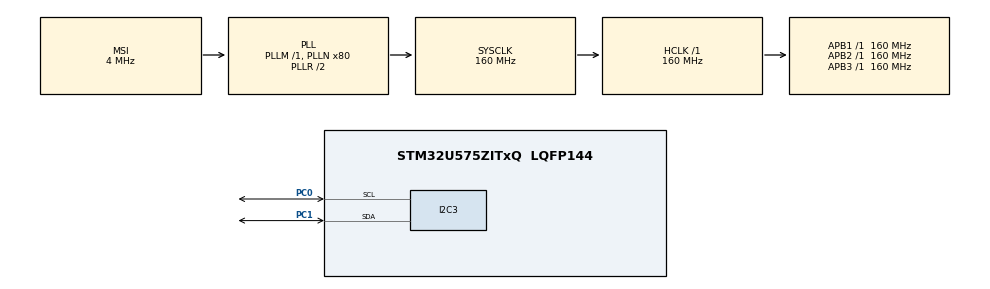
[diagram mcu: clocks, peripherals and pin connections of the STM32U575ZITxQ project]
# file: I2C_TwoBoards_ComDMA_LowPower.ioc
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CORTEX_M33_NS.userName=CORTEX_M33
I2C3.AddressingMode=I2C_ADDRESSINGMODE_10BIT
I2C3.OwnAddress=0x30F
I2C3.Timing=0x00303D5B
LPDMA1.LINKALLOCATEDPORT_LPDMACH0=DMA_LINK_ALLOCATED_PORT1
LPDMA1.LINKALLOCATEDPORT_LPDMACH1=DMA_LINK_ALLOCATED_PORT1
LPDMA1.PRIORITY_LL_LPDMACH0=DMA_HIGH_PRIORITY
LPDMA1.PRIORITY_LL_LPDMACH1=DMA_HIGH_PRIORITY
Linkedlist.MDMA_Channel0.GP_SW.0.BlkHWRequest=DMA_BREQ_SINGLE_BURST
Linkedlist.MDMA_Channel0.GP_SW.0.DataHandling=NONE
Linkedlist.MDMA_Channel0.GP_SW.0.DataSize=0
Linkedlist.MDMA_Channel0.GP_SW.0.DestDataWidth=DMA_DEST_DATAWIDTH_BYTE
Linkedlist.MDMA_Channel0.GP_SW.0.DestInc=DMA_DINC_FIXED
Linkedlist.MDMA_Channel0.GP_SW.0.Direction=DMA_MEMORY_TO_PERIPH
Linkedlist.MDMA_Channel0.GP_SW.0.DstAddress=0
Linkedlist.MDMA_Channel0.GP_SW.0.Instance=MDMA_Channel0
Linkedlist.MDMA_Channel0.GP_SW.0.LL_MASTERDMA=LPDMA
Linkedlist.MDMA_Channel0.GP_SW.0.LL_NAME=Queue_tx
Linkedlist.MDMA_Channel0.GP_SW.0.LL_TYPE=LINEAR
Linkedlist.MDMA_Channel0.GP_SW.0.NODE_NAME=Node_tx
Linkedlist.MDMA_Channel0.GP_SW.0.Requestforcodegen=LPDMA1_REQUEST_I2C3_TX
Linkedlist.MDMA_Channel0.GP_SW.0.SrcAddress=0
Linkedlist.MDMA_Channel0.GP_SW.0.SrcDataWidth=DMA_SRC_DATAWIDTH_BYTE
Linkedlist.MDMA_Channel0.GP_SW.0.SrcInc=DMA_SINC_INCREMENTED
Linkedlist.MDMA_Channel0.GP_SW.0.TransferEventMode=DMA_TCEM_BLOCK_TRANSFER
Linkedlist.MDMA_Channel0.GP_SW.0.TriggerPolarity=DMA_TRIG_POLARITY_MASKED
Linkedlist.MDMA_Channel0.Request0=GP_SW
Linkedlist.MDMA_Channel0.RequestsNb=1
Linkedlist.MDMA_Channel1.GP_SW.0.BlkHWRequest=DMA_BREQ_SINGLE_BURST
Linkedlist.MDMA_Channel1.GP_SW.0.DataHandling=NONE
Linkedlist.MDMA_Channel1.GP_SW.0.DataSize=0
Linkedlist.MDMA_Channel1.GP_SW.0.DestDataWidth=DMA_DEST_DATAWIDTH_BYTE
Linkedlist.MDMA_Channel1.GP_SW.0.DestInc=DMA_DINC_INCREMENTED
Linkedlist.MDMA_Channel1.GP_SW.0.Direction=DMA_PERIPH_TO_MEMORY
Linkedlist.MDMA_Channel1.GP_SW.0.DstAddress=0
Linkedlist.MDMA_Channel1.GP_SW.0.Instance=MDMA_Channel1
Linkedlist.MDMA_Channel1.GP_SW.0.LL_MASTERDMA=LPDMA
Linkedlist.MDMA_Channel1.GP_SW.0.LL_NAME=Queue_rx
Linkedlist.MDMA_Channel1.GP_SW.0.LL_TYPE=LINEAR
Linkedlist.MDMA_Channel1.GP_SW.0.NODE_NAME=Node_rx
Linkedlist.MDMA_Channel1.GP_SW.0.Requestforcodegen=LPDMA1_REQUEST_I2C3_RX
Linkedlist.MDMA_Channel1.GP_SW.0.SrcAddress=0
Linkedlist.MDMA_Channel1.GP_SW.0.SrcDataWidth=DMA_SRC_DATAWIDTH_BYTE
Linkedlist.MDMA_Channel1.GP_SW.0.SrcInc=DMA_SINC_FIXED
Linkedlist.MDMA_Channel1.GP_SW.0.TransferEventMode=DMA_TCEM_BLOCK_TRANSFER
Linkedlist.MDMA_Channel1.GP_SW.0.TriggerPolarity=DMA_TRIG_POLARITY_MASKED
Linkedlist.MDMA_Channel1.Request0=GP_SW
Linkedlist.MDMA_Channel1.RequestsNb=1
Linkedlist.RequestSet0=MDMA_Channel0
Linkedlist.RequestSet1=MDMA_Channel1
Linkedlist.RequestSetsNb=2
Mcu.Family=STM32U5
Mcu.Name=STM32U575ZITxQ
Mcu.Package=LQFP144
NVIC.I2C3_ER_IRQn=true\:0\:0\:false\:false\:true\:true\:true\:true
NVIC.I2C3_EV_IRQn=true\:0\:0\:false\:false\:true\:true\:true\:true
NVIC.LPDMA1_Channel0_IRQn=true\:0\:0\:false\:false\:true\:true\:true\:true
NVIC.LPDMA1_Channel1_IRQn=true\:0\:0\:false\:false\:true\:true\:true\:true
NVIC.PriorityGroup=NVIC_PRIORITYGROUP_4
PC0.GPIO_Pu=GPIO_PULLUP
PC0.GPIO_Speed=GPIO_SPEED_FREQ_HIGH
PC0.Mode=I2C
PC0.Signal=I2C3_SCL
PC1.GPIO_Pu=GPIO_PULLUP
PC1.GPIO_Speed=GPIO_SPEED_FREQ_HIGH
PC1.Mode=I2C
PC1.Signal=I2C3_SDA
PWR.PowerMode=PWR_SMPS_SUPPLY
ProjectManager.HeapSize=0x200
ProjectManager.StackSize=0x400
ProjectManager.TargetToolchain=EWARM V8.50
RCC.ADCFreq_Value=16000000
RCC.AHBFreq_Value=160000000
RCC.APB1Freq_Value=160000000
RCC.APB1TimFreq_Value=160000000
RCC.APB2Freq_Value=160000000
RCC.APB2TimFreq_Value=160000000
RCC.APB3Freq_Value=160000000
RCC.CortexFreq_Value=160000000
RCC.DACCLockSelectionVirtual=RCC_DAC1CLKSOURCE_LSI
RCC.DACCLockSelectionVirtualString=RCC_DAC1CLKSOURCE_LSI
RCC.EPOD_VALUE=4000000
RCC.HCLKFreq_Value=160000000
RCC.HSE_VALUE=16000000
RCC.HSI48_VALUE=48000000
RCC.HSI_VALUE=16000000
RCC.I2C3CLockSelection=RCC_I2C3CLKSOURCE_HSI
RCC.LSE_VALUE=32768
RCC.LSIDIV_VALUE=32000
RCC.MSI_VALUE=4000000
RCC.PLLN=80
RCC.SYSCLKFreq_VALUE=160000000
RCC.SYSCLKSource=RCC_SYSCLKSOURCE_PLLCLK
RCC.USBFreq_Value=48000000
RCC.VCOOutputFreq_Value=320000000
VP_ICACHE_VS_ICACHE.Mode=DirectMappedCache
VP_LPBAMQUEUE_VS_QUEUE.Mode=QUEUEMODE
VP_LPBAM_VS_SIG1.Mode=SmartRun
VP_LPBAM_VS_SIG4.Mode=LPDMA1
VP_LPDMA1_VS_LPDMACH0.Mode=LINKEDLIST_LPDMACH0
VP_LPDMA1_VS_LPDMACH1.Mode=LINKEDLIST_LPDMACH1
VP_PWR_VS_DBSignals.Mode=DisableDeadBatterySignals
VP_PWR_VS_LPOM.Mode=PowerOptimisation
VP_PWR_VS_SECSignals.Mode=Security/Privilege
board=custom

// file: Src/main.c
/* USER CODE BEGIN Header */
/**
  ******************************************************************************
  * @file           : main.c
  * @brief          : Main program body
  ******************************************************************************
  * @attention
  *
  * Copyright (c) 2021 STMicroelectronics.
  * All rights reserved.
  *
  * This software is licensed under terms that can be found in the LICENSE file
  * in the root directory of this software component.
  * If no LICENSE file comes with this software, it is provided AS-IS.
  *
  ******************************************************************************
  */
/* USER CODE END Header */
#include "main.h"

/* USER CODE BEGIN PD */
/* Uncomment this line to use the board as master, if not it is used as slave */
#define MASTER_BOARD
#define I2C_ADDRESS          0x30F

/* Buffer used for transmission */
uint8_t aTxBuffer[] = " ****I2C_TwoBoards communication based on DMA****  ****I2C_TwoBoards communication based on DMA****  ****I2C_TwoBoards communication based on DMA**** ";

/* Buffer used for reception */
uint8_t aRxBuffer[RXBUFFERSIZE];
/* USER CODE END PD */

I2C_HandleTypeDef hi2c3;

DMA_HandleTypeDef handle_LPDMA1_Channel0;
DMA_HandleTypeDef handle_LPDMA1_Channel1;

void SystemClock_Config(void);
static void SystemPower_Config(void);
static void MX_GPIO_Init(void);
static void MX_LPDMA1_Init(void);
static void MX_ICACHE_Init(void);
static void MX_I2C3_Init(void);
/* USER CODE BEGIN PFP */
#ifndef MASTER_BOARD
static uint16_t Buffercmp(uint8_t* pBuffer1, uint8_t* pBuffer2, uint16_t BufferLength);
#endif /* MASTER_BOARD */
/* USER CODE END PFP */

int main(void)
{

  /* USER CODE BEGIN 1 */
  /* STM32U5xx HAL library initialization:
       - Configure the Flash prefetch
       - Configure the Systick to generate an interrupt each 1 msec
       - Set NVIC Group Priority to 3
       - Low Level Initialization
     */
  /* USER CODE END 1 */

  /* MCU Configuration--------------------------------------------------------*/

  /* Reset of all peripherals, Initializes the Flash interface and the Systick. */
  HAL_Init();

  /* Configure the System Power */
  SystemPower_Config();

  /* Configure the system clock */
  SystemClock_Config();

  /* USER CODE BEGIN SysInit */
  /* Configure LED1, LED2 and LED3 */
  BSP_LED_Init(LED1);
  BSP_LED_Init(LED2);
  BSP_LED_Init(LED3);
  /* USER CODE END SysInit */

  /* Initialize all configured peripherals */
  MX_GPIO_Init();
  MX_LPDMA1_Init();
  MX_ICACHE_Init();
  MX_I2C3_Init();
  /* USER CODE BEGIN 2 */
  MX_Queue_tx_Config();
  HAL_DMAEx_List_LinkQ(&handle_LPDMA1_Channel1, &Queue_tx);
  __HAL_LINKDMA(&hi2c3, hdmatx, handle_LPDMA1_Channel1);
  MX_Queue_rx_Config();
  HAL_DMAEx_List_LinkQ(&handle_LPDMA1_Channel0, &Queue_rx);
  __HAL_LINKDMA(&hi2c3, hdmarx, handle_LPDMA1_Channel0);

#ifdef MASTER_BOARD

  /* Configure User push-button */
  BSP_PB_Init(BUTTON_USER,BUTTON_MODE_GPIO);

  /* Wait for User push-button press before starting the Communication */
  while (BSP_PB_GetState(BUTTON_USER) != GPIO_PIN_SET)
  {
    BSP_LED_Toggle(LED2);
    HAL_Delay(100);
  }
  BSP_LED_Off(LED2);

  /* Delay to avoid that possible signal rebound is taken as button release */
  HAL_Delay(50);

  /* Wait for User push-button release before starting the Communication */
  while (BSP_PB_GetState(BUTTON_USER) != GPIO_PIN_RESET)
  {
  }

  /* The board sends the message and expects to receive it back */

  /*##-2- Start the transmission process #####################################*/
  /* While the I2C in reception process, user can transmit data through
     "aTxBuffer" buffer */
  do
  {
    if(HAL_I2C_Master_Transmit_DMA(&hi2c3, (uint16_t)I2C_ADDRESS, (uint8_t*)aTxBuffer, TXBUFFERSIZE)!= HAL_OK)
    {
      /* Error_Handler() function is called when error occurs. */
      Error_Handler();
    }

    /*##-3- Wait for the end of the transfer #################################*/
    /*  Before starting a new communication transfer, you need to check the current
        state of the peripheral; if it is busy you need to wait for the end of current
        transfer before starting a new one.
        For simplicity reasons, this example is just waiting till the end of the
        transfer, but application may perform other tasks while transfer operation
        is ongoing. */
    while (HAL_I2C_GetState(&hi2c3) != HAL_I2C_STATE_READY)
    {
    }

    /* When Acknowledge failure occurs (Slave don't acknowledge it is address)
       Master restarts communication */
  }
  while(HAL_I2C_GetError(&hi2c3) == HAL_I2C_ERROR_AF);

  /* Turn LED1 on: Transfer in Transmission process is correct */
  BSP_LED_On(LED1);

#else

  /* The board receives the message and sends it back */

  /*##-2- Put I2C peripheral in reception process ###########################*/
  /* Enable wakeup from stop mode */
  HAL_I2CEx_EnableWakeUp(&hi2c3);
  if(HAL_I2C_Slave_Receive_DMA(&hi2c3, (uint8_t *)aRxBuffer, RXBUFFERSIZE) != HAL_OK)

  {
    /* Transfer error in reception process */
    Error_Handler();
  }

  /* Remain ADDR cleared by Hardware */
  __HAL_I2C_DISABLE_IT(&hi2c3, I2C_IT_ADDRI);
  hi2c3.Instance->CR1 |= I2C_CR1_ADDRACLR;

  /* Enable STOPI to wake up from LP Mode */
  __HAL_I2C_ENABLE_IT(&hi2c3, I2C_IT_STOPI);

  /* Enter the system to stop 2 mode */
  HAL_PWREx_EnterSTOP2Mode(PWR_STOPENTRY_WFE);

  /* Check that the system was resumed from stop 2 */
  if ((READ_BIT(PWR->CR1, PWR_CR1_LPMS) != PWR_CR1_LPMS_1) || \
    (__HAL_PWR_GET_FLAG(PWR_FLAG_STOPF) == 0U))
  {
    while(1); /* KO */
  }
  /* Clear stop flag */
  __HAL_PWR_CLEAR_FLAG(PWR_FLAG_STOPF);

  /* Check that stop flag is cleared */
  if (__HAL_PWR_GET_FLAG(PWR_FLAG_STOPF) != 0U)
  {
    while(1); /* KO */
  }

  /*##-3- Wait for the end of the transfer ###################################*/
  /*  Before starting a new communication transfer, you need to check the current
      state of the peripheral; if it is busy you need to wait for the end of current
      transfer before starting a new one.
      For simplicity reasons, this example is just waiting till the end of the
      transfer, but application may perform other tasks while transfer operation
      is ongoing. */
  while (HAL_I2C_GetState(&hi2c3) != HAL_I2C_STATE_READY)
  {
  }

  /* Turn LED1 on: Transfer in reception process is correct */
  BSP_LED_On(LED1);

  /*##-6- Compare the sent and received buffers ##############################*/
  if(Buffercmp((uint8_t*)aTxBuffer,(uint8_t*)aRxBuffer,RXBUFFERSIZE))
  {
    /* Processing Error */
    Error_Handler();
  }

#endif /* MASTER_BOARD */
  /* USER CODE END 2 */

  /* Infinite loop */
  while (1)
  {

  }
}

void SystemClock_Config(void)
{
  RCC_OscInitTypeDef RCC_OscInitStruct = {0};
  RCC_ClkInitTypeDef RCC_ClkInitStruct = {0};

  /** Configure the main internal regulator output voltage
  */
  if (HAL_PWREx_ControlVoltageScaling(PWR_REGULATOR_VOLTAGE_SCALE1) != HAL_OK)
  {
    Error_Handler();
  }

  /** Initializes the CPU, AHB and APB buses clocks
  */
  RCC_OscInitStruct.OscillatorType = RCC_OSCILLATORTYPE_HSI|RCC_OSCILLATORTYPE_MSI;
  RCC_OscInitStruct.HSIState = RCC_HSI_ON;
  RCC_OscInitStruct.HSICalibrationValue = RCC_HSICALIBRATION_DEFAULT;
  RCC_OscInitStruct.MSIState = RCC_MSI_ON;
  RCC_OscInitStruct.MSICalibrationValue = RCC_MSICALIBRATION_DEFAULT;
  RCC_OscInitStruct.MSIClockRange = RCC_MSIRANGE_4;
  RCC_OscInitStruct.PLL.PLLState = RCC_PLL_ON;
  RCC_OscInitStruct.PLL.PLLSource = RCC_PLLSOURCE_MSI;
  RCC_OscInitStruct.PLL.PLLMBOOST = RCC_PLLMBOOST_DIV1;
  RCC_OscInitStruct.PLL.PLLM = 1;
  RCC_OscInitStruct.PLL.PLLN = 80;
  RCC_OscInitStruct.PLL.PLLP = 2;
  RCC_OscInitStruct.PLL.PLLQ = 2;
  RCC_OscInitStruct.PLL.PLLR = 2;
  RCC_OscInitStruct.PLL.PLLRGE = RCC_PLLVCIRANGE_0;
  RCC_OscInitStruct.PLL.PLLFRACN = 0;
  if (HAL_RCC_OscConfig(&RCC_OscInitStruct) != HAL_OK)
  {
    Error_Handler();
  }

  /** Initializes the CPU, AHB and APB buses clocks
  */
  RCC_ClkInitStruct.ClockType = RCC_CLOCKTYPE_HCLK|RCC_CLOCKTYPE_SYSCLK
                              |RCC_CLOCKTYPE_PCLK1|RCC_CLOCKTYPE_PCLK2
                              |RCC_CLOCKTYPE_PCLK3;
  RCC_ClkInitStruct.SYSCLKSource = RCC_SYSCLKSOURCE_PLLCLK;
  RCC_ClkInitStruct.AHBCLKDivider = RCC_SYSCLK_DIV1;
  RCC_ClkInitStruct.APB1CLKDivider = RCC_HCLK_DIV1;
  RCC_ClkInitStruct.APB2CLKDivider = RCC_HCLK_DIV1;
  RCC_ClkInitStruct.APB3CLKDivider = RCC_HCLK_DIV1;

  if (HAL_RCC_ClockConfig(&RCC_ClkInitStruct, FLASH_LATENCY_4) != HAL_OK)
  {
    Error_Handler();
  }
}

/**
  * @brief Power Configuration
  * @retval None
  */
static void SystemPower_Config(void)
{

  /*
   * Disable the internal Pull-Up in Dead Battery pins of UCPD peripheral
   */
  HAL_PWREx_DisableUCPDDeadBattery();

  /*
   * Switch to SMPS regulator instead of LDO
   */
  if (HAL_PWREx_ConfigSupply(PWR_SMPS_SUPPLY) != HAL_OK)
  {
    Error_Handler();
  }
}

static void MX_I2C3_Init(void)
{

  hi2c3.Instance = I2C3;
  hi2c3.Init.Timing = 0x00303D5B;
  hi2c3.Init.OwnAddress1 = 0x30F;
  hi2c3.Init.AddressingMode = I2C_ADDRESSINGMODE_10BIT;
  hi2c3.Init.DualAddressMode = I2C_DUALADDRESS_DISABLE;
  hi2c3.Init.OwnAddress2 = 0;
  hi2c3.Init.OwnAddress2Masks = I2C_OA2_NOMASK;
  hi2c3.Init.GeneralCallMode = I2C_GENERALCALL_DISABLE;
  hi2c3.Init.NoStretchMode = I2C_NOSTRETCH_DISABLE;
  if (HAL_I2C_Init(&hi2c3) != HAL_OK)
  {
    Error_Handler();
  }

  /** Configure Analogue filter
  */
  if (HAL_I2CEx_ConfigAnalogFilter(&hi2c3, I2C_ANALOGFILTER_ENABLE) != HAL_OK)
  {
    Error_Handler();
  }

  /** Configure Digital filter
  */
  if (HAL_I2CEx_ConfigDigitalFilter(&hi2c3, 0) != HAL_OK)
  {
    Error_Handler();
  }

}

static void MX_ICACHE_Init(void)
{

  /** Enable instruction cache in 1-way (direct mapped cache)
  */
  if (HAL_ICACHE_ConfigAssociativityMode(ICACHE_1WAY) != HAL_OK)
  {
    Error_Handler();
  }
  if (HAL_ICACHE_Enable() != HAL_OK)
  {
    Error_Handler();
  }

}

static void MX_LPDMA1_Init(void)
{

  /* USER CODE BEGIN LPDMA1_Init 0 */
    DMAx_CLKAM_ENABLE();
    DMAx_CLK_SLEEP_ENABLE();
  /* USER CODE END LPDMA1_Init 0 */

  /* Peripheral clock enable */
  __HAL_RCC_LPDMA1_CLK_ENABLE();

  /* LPDMA1 interrupt Init */
    HAL_NVIC_SetPriority(LPDMA1_Channel0_IRQn, 0, 0);
    HAL_NVIC_EnableIRQ(LPDMA1_Channel0_IRQn);
    HAL_NVIC_SetPriority(LPDMA1_Channel1_IRQn, 0, 0);
    HAL_NVIC_EnableIRQ(LPDMA1_Channel1_IRQn);

  handle_LPDMA1_Channel0.Instance = LPDMA1_Channel0;
  handle_LPDMA1_Channel0.InitLinkedList.Priority = DMA_HIGH_PRIORITY;
  handle_LPDMA1_Channel0.InitLinkedList.LinkStepMode = DMA_LSM_FULL_EXECUTION;
  handle_LPDMA1_Channel0.InitLinkedList.LinkAllocatedPort = DMA_LINK_ALLOCATED_PORT1;
  handle_LPDMA1_Channel0.InitLinkedList.TransferEventMode = DMA_TCEM_LAST_LL_ITEM_TRANSFER;
  handle_LPDMA1_Channel0.InitLinkedList.LinkedListMode = DMA_LINKEDLIST_NORMAL;
  if (HAL_DMAEx_List_Init(&handle_LPDMA1_Channel0) != HAL_OK)
  {
    Error_Handler();
  }
  if (HAL_DMA_ConfigChannelAttributes(&handle_LPDMA1_Channel0, DMA_CHANNEL_NPRIV) != HAL_OK)
  {
    Error_Handler();
  }
  handle_LPDMA1_Channel1.Instance = LPDMA1_Channel1;
  handle_LPDMA1_Channel1.InitLinkedList.Priority = DMA_HIGH_PRIORITY;
  handle_LPDMA1_Channel1.InitLinkedList.LinkStepMode = DMA_LSM_FULL_EXECUTION;
  handle_LPDMA1_Channel1.InitLinkedList.LinkAllocatedPort = DMA_LINK_ALLOCATED_PORT1;
  handle_LPDMA1_Channel1.InitLinkedList.TransferEventMode = DMA_TCEM_LAST_LL_ITEM_TRANSFER;
  handle_LPDMA1_Channel1.InitLinkedList.LinkedListMode = DMA_LINKEDLIST_NORMAL;
  if (HAL_DMAEx_List_Init(&handle_LPDMA1_Channel1) != HAL_OK)
  {
    Error_Handler();
  }
  if (HAL_DMA_ConfigChannelAttributes(&handle_LPDMA1_Channel1, DMA_CHANNEL_NPRIV) != HAL_OK)
  {
    Error_Handler();
  }

}

static void MX_GPIO_Init(void)
{

  /* GPIO Ports Clock Enable */
  __HAL_RCC_GPIOC_CLK_ENABLE();

}

/* USER CODE BEGIN 4 */
/**
  * @brief  Tx Transfer completed callback.
  * @param  hi2c3: I2C handle.
  * @note   This example shows a simple way to report end of DMA Tx transfer, and
  *         you can add your own implementation.
  * @retval None
  */
#ifdef MASTER_BOARD
void HAL_I2C_MasterTxCpltCallback(I2C_HandleTypeDef *hi2c3)
{
  /* Toggle LED1: Transfer in transmission process is correct */
  BSP_LED_Toggle(LED1);
}
#else
void HAL_I2C_SlaveTxCpltCallback(I2C_HandleTypeDef *hi2c3)
{
  /* Toggle LED1: Transfer in transmission process is correct */
  BSP_LED_Toggle(LED1);
}
#endif /* MASTER_BOARD */

/**
  * @brief  Rx Transfer completed callback.
  * @param  hi2c3: I2C handle
  * @note   This example shows a simple way to report end of DMA Rx transfer, and
  *         you can add your own implementation.
  * @retval None
  */
#ifdef MASTER_BOARD
void HAL_I2C_MasterRxCpltCallback(I2C_HandleTypeDef *hi2c3)
{
  /* Toggle LED1: Transfer in reception process is correct */
  BSP_LED_Toggle(LED1);
}
#else
void HAL_I2C_SlaveRxCpltCallback(I2C_HandleTypeDef *hi2c3)
{
  /* Toggle LED1: Transfer in reception process is correct */
  BSP_LED_Toggle(LED1);
}
#endif /* MASTER_BOARD */

/**
  * @brief  I2C error callbacks.
  * @param  hi2c3: I2C handle
  * @note   This example shows a simple way to report transfer error, and you can
  *         add your own implementation.
  * @retval None
  */
void HAL_I2C_ErrorCallback(I2C_HandleTypeDef *hi2c3)
{
  /** Error_Handler() function is called when error occurs.
    * 1- When Slave doesn't acknowledge its address, Master restarts communication.
    * 2- When Master doesn't acknowledge the last data transferred, Slave doesn't care in this example.
    */
  if (HAL_I2C_GetError(hi2c3) != HAL_I2C_ERROR_AF)
  {
    /* Turn Off LED1 */
    BSP_LED_Off(LED1);

    /* Turn On LED3 */
    BSP_LED_On(LED3);
  }
}

#ifndef MASTER_BOARD
/**
  * @brief  Compares two buffers.
  * @param  pBuffer1, pBuffer2: buffers to be compared.
  * @param  BufferLength: buffer's length
  * @retval 0  : pBuffer1 identical to pBuffer2
  *         >0 : pBuffer1 differs from pBuffer2
  */
static uint16_t Buffercmp(uint8_t* pBuffer1, uint8_t* pBuffer2, uint16_t BufferLength)
{
  while (BufferLength--)
  {
    if ((*pBuffer1) != *pBuffer2)
    {
      return BufferLength;
    }
    pBuffer1++;
    pBuffer2++;
  }

  return 0;
}
#endif /* MASTER_BOARD */
/* USER CODE END 4 */

void Error_Handler(void)
{
  /* USER CODE BEGIN Error_Handler_Debug */
  /* User can add his own implementation to report the HAL error return state */
  __disable_irq();
  /* Turn LED1 off */
  BSP_LED_Off(LED1);
  /* Turn LED3 on */
  BSP_LED_On(LED3);
  while (1)
  {
  }
  /* USER CODE END Error_Handler_Debug */
}
